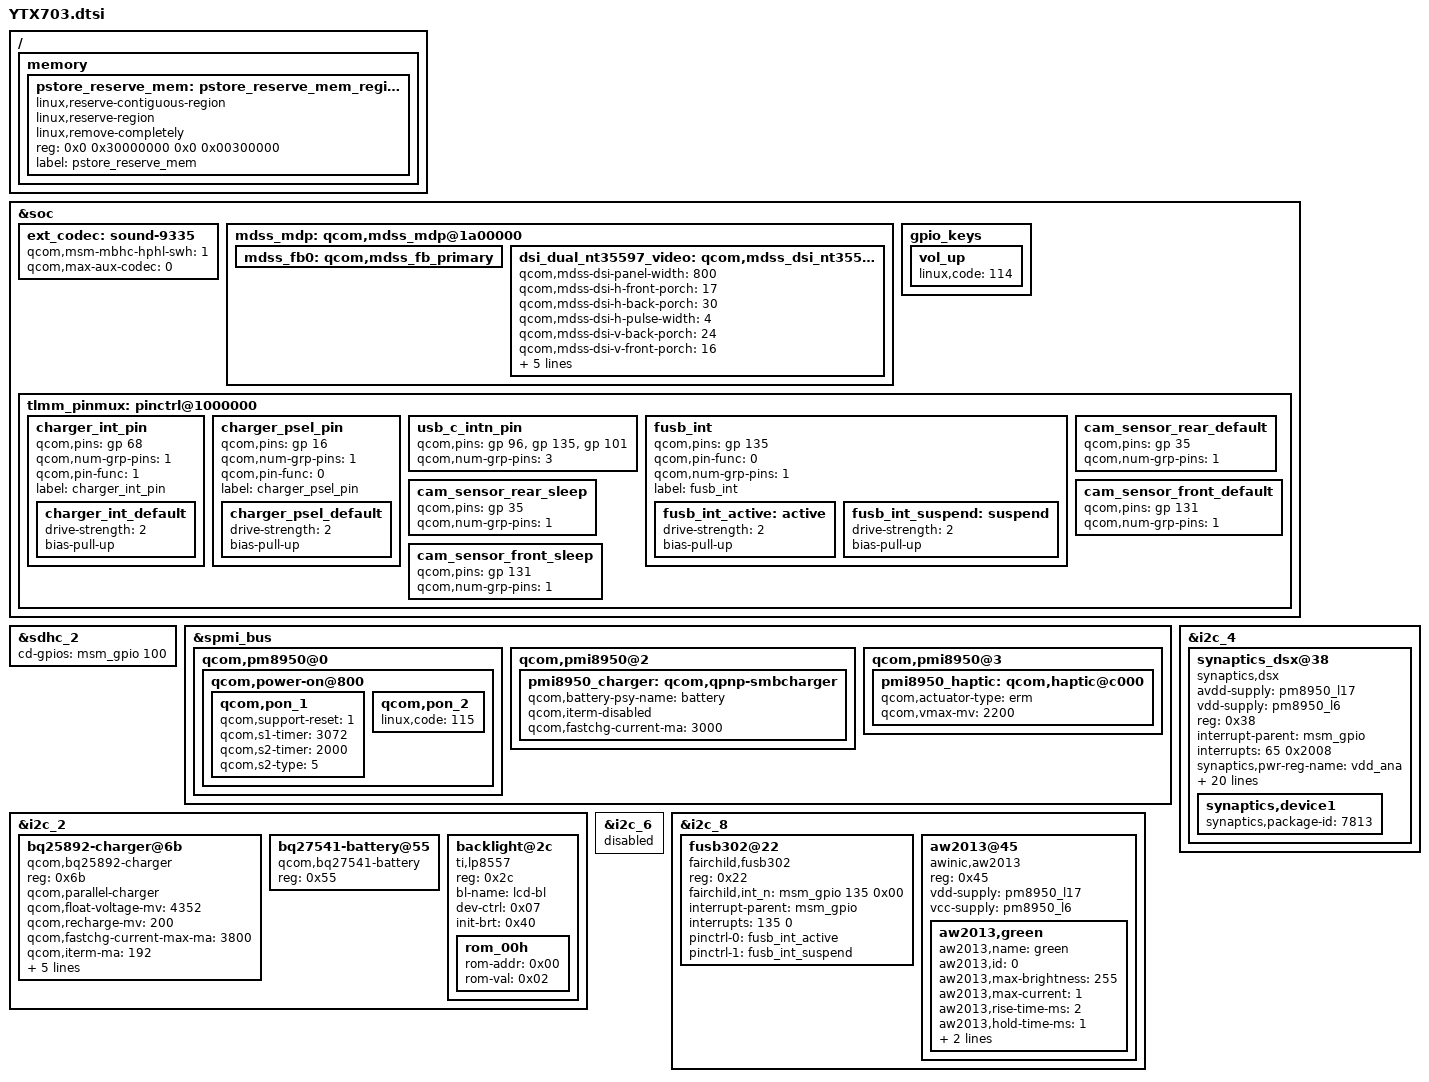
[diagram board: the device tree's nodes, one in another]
/*
 * Copyright (c) 2018, The Linux Foundation. All rights reserved.
 *
 * This program is free software; you can redistribute it and/or modify
 * it under the terms of the GNU General Public License version 2 and
 * only version 2 as published by the Free Software Foundation.
 *
 * This program is distributed in the hope that it will be useful,
 * but WITHOUT ANY WARRANTY; without even the implied warranty of
 * MERCHANTABILITY or FITNESS FOR A PARTICULAR PURPOSE.  See the
 * GNU General Public License for more details.
 */

#include "YTX703-camera-sensor.dtsi"

/ {
	/* reserve memory region for pstore: */
	memory {
		pstore_reserve_mem: pstore_reserve_mem_region@0 {
			linux,reserve-contiguous-region;
			linux,reserve-region;
			linux,remove-completely;
			reg = <0x0 0x30000000 0x0 0x00300000>;
			label = "pstore_reserve_mem";
		};
	};
};

&soc {
	/* sound configuration */
	ext_codec: sound-9335 {
		qcom,msm-mbhc-hphl-swh = <1>; /* headphone detection */
		qcom,max-aux-codec = <0>;
	};
	/* disable kernel boot-logo: */
	mdss_mdp: qcom,mdss_mdp@1a00000 {
		mdss_fb0: qcom,mdss_fb_primary {
			/delete-property/ qcom,mdss-fb-splash-logo-enabled;
		};
	};
	/* Compensate for hardware-reversed VOL-UP and VOL-DOWN buttons */
	gpio_keys {
		vol_up {
			linux,code = <114>; /* KEY_VOLUMEDOWN */
		};
	};
	/* pin configuration */
	tlmm_pinmux: pinctrl@1000000 {
		/* charger pins: */
		charger_int_pin {
			qcom,pins = <&gp 68>;
			qcom,num-grp-pins = <1>;
			qcom,pin-func = <1>;
			label = "charger_int_pin";
			charger_int_default: charger_int_default {
				drive-strength = <2>; /* 2 MA */
				bias-pull-up; /* PULL UP*/
			};
		};
		charger_psel_pin {
			qcom,pins = <&gp 16>;
			qcom,num-grp-pins = <1>;
			qcom,pin-func = <0>;
			label = "charger_psel_pin";
			charger_psel_default:  charger_psel_default {
				drive-strength = <2>; /* 2 MA */
				bias-pull-up; /* PULL UP*/
			};
		};
		/* USB pins: */
		usb_c_intn_pin {
			qcom,pins = <&gp 96>, <&gp 135>, <&gp 101>;
			qcom,num-grp-pins = <3>;
		};
		fusb_int {
			qcom,pins = <&gp 135>;
			qcom,pin-func = <0>;
			qcom,num-grp-pins = <1>;
			label = "fusb_int";
			fusb_int_active: active {
				drive-strength = <2>;
				bias-pull-up;
			};
			fusb_int_suspend: suspend {
				drive-strength = <2>;
				bias-pull-up;
			};
		};
		/* camera pins: */
		cam_sensor_rear_default {  /* STANDBY */
			qcom,pins = <&gp 35>;
			qcom,num-grp-pins = <1>;
		};
		cam_sensor_rear_sleep {    /* STANDBY */
			qcom,pins = <&gp 35>;
			qcom,num-grp-pins = <1>;
		};
		cam_sensor_front_default { /* RESET, STANDBY */
			qcom,pins = <&gp 131>;
			qcom,num-grp-pins = <1>;
		};
		cam_sensor_front_sleep {   /* RESET, STANDBY */
			qcom,pins = <&gp 131>;
			qcom,num-grp-pins = <1>;
		};
	};
};

/* SD-card GPIO */
&sdhc_2 {
	cd-gpios = <&msm_gpio 100 0x0>;
};

/* SPMI configuration */
&spmi_bus {
	/* power-button configuration: */
	qcom,pm8950@0 {
		qcom,power-on@800 {
			qcom,pon_1 {
				qcom,support-reset = <1>;
				qcom,s1-timer = <3072>; /* forced power off */
				qcom,s2-timer = <2000>; /* than reboot */
				qcom,s2-type = <5>;
			};
			/* Compensate for hardware-reversed VOL-UP and VOL-DOWN buttons */
			qcom,pon_2 {
				linux,code = <115>; /* KEY_VOLUMEUP */
			};
		};
	};
	/* smbcharger configuration: */
	qcom,pmi8950@2 {
		pmi8950_charger: qcom,qpnp-smbcharger {
			/delete-property/ qcom,iterm-ma;
			/delete-property/ qcom,float-voltage-mv;
			/delete-property/ qcom,resume-delta-mv;
			qcom,battery-psy-name= "battery";
			/delete-property/ qcom,autoadjust-vfloat;
			/delete-property/ qcom,force-aicl-rerun;
			/delete-property/ qcom,aicl-rerun-period-s;
			/delete-property/ qcom,charging-disabled;
			qcom,iterm-disabled;
			qcom,fastchg-current-ma = <3000>;
		};
	};
	/* vibrator settings: */
	qcom,pmi8950@3 {
		pmi8950_haptic: qcom,haptic@c000 {
			qcom,actuator-type = "erm";
			qcom,vmax-mv = <2200>;
		};
	};
};

/* I2C configuration */
&i2c_2 {
	/* parallel-charger configuration: */
	bq25892-charger@6b {
		compatible = "qcom,bq25892-charger";
		reg = <0x6b>;
		qcom,parallel-charger;
		qcom,float-voltage-mv = <4352>;
		qcom,recharge-mv = <200>;
		qcom,fastchg-current-max-ma = <3800>;
		qcom,iterm-ma = <192>;
		interrupt-parent = <&msm_gpio>;
		interrupts = <68 0>;
		pinctrl-names = "default";
		pinctrl-0 = <&charger_int_default &charger_psel_default>;
		qcom,psel-gpio = <&msm_gpio 16 0>;
	};

	bq27541-battery@55 {
		compatible = "qcom,bq27541-battery";
		reg = <0x55>;
	};

	backlight@2c {
		compatible = "ti,lp8557";
		reg = <0x2c>;
		bl-name = "lcd-bl";
		dev-ctrl = /bits/ 8 <0x07>; /* see lp8557 documentation */
		init-brt = /bits/ 8 <0x40>; /* 25% brightness */
		 /* enable spread-spectrum boost clocking (reduces flickering): */
		rom_00h {
			rom-addr = /bits/ 8 <0x00>;
			rom-val  = /bits/ 8 <0x02>;
		};
	};
};

&i2c_4 { /* BLSP1 QUP4 */
	/delete-node/ synaptics@20;
	/* touchscreen configuration: */
	synaptics_dsx@38 {
		/* use with driver v2.0: */
		compatible  = "synaptics,dsx";
		avdd-supply = <&pm8950_l17>;
		vdd-supply  = <&pm8950_l6>;
		/* use with driver v2.6: */
		//compatible = "synaptics,dsx-i2c";
		//vdd_ana-supply = <&pm8950_l17>;
		//vcc_i2c-supply = <&pm8950_l6>;
		reg = <0x38>;
		interrupt-parent = <&msm_gpio>;
		interrupts       = <65 0x2008>;
		synaptics,pwr-reg-name = "vdd_ana";
		synaptics,bus-reg-name = "vcc_i2c";
		clock-names = "iface_clk", "core_clk";
		clocks = <&clock_gcc clk_gcc_blsp1_ahb_clk>,
		         <&clock_gcc clk_gcc_blsp1_qup4_i2c_apps_clk>;
		/* pins used by touchscreen: */
		pinctrl-names = "pmx_ts_active","pmx_ts_suspend","pmx_ts_release";
		pinctrl-0 = <&ts_int_active  &ts_reset_active>;
		pinctrl-1 = <&ts_int_suspend &ts_reset_suspend>;
		pinctrl-2 = <&ts_release>;
		synaptics,irq-gpio   = <&msm_gpio 65 0x2008>;
		synaptics,reset-gpio = <&msm_gpio 64 0x0>;
		synaptics,disable-gpios;
		synaptics,detect-device;
		synaptics,i2c-pull-up;
		synaptics,ub-i2c-addr = <0x38>;
		synaptics,power-down;
		synaptics,power-delay-ms  = <60>;
		synaptics,reset-on-state  = <0>;
		synaptics,reset-active-ms = <10>;
		synaptics,reset-delay-ms  = <60>;
		synaptics,irq-flags = <0x2008>; /* IRQF_ONESHOT | IRQF_TRIGGER_LOW */
		/* swap and flip to allow rotation hack: */
		synaptics,swap-axes;
		synaptics,y-flip;
		synaptics,device1 {
			synaptics,package-id = <7813>;
		};
	};
};

&i2c_6 { /* BLSP2 QUP2 */
	status = "disabled"; /* disable unused I2C bus */
	/delete-node/ nq@2b; /* remove NFC node */
};

&i2c_8 { /* BLSP2 QUP4 */
	/* USB-controller configuration: */
	fusb302@22 {
		compatible = "fairchild,fusb302";
		reg = <0x22>;
		fairchild,int_n  = <&msm_gpio 135 0x00>;
		interrupt-parent = <&msm_gpio>;
		interrupts = <135 0>; /* MSM GPIO 102 */
		interrupt-names = "fsc_interrupt_int_n";
		pinctrl-names = "fusb_active", "fusb_suspend";
		pinctrl-0 = <&fusb_int_active>;
		pinctrl-1 = <&fusb_int_suspend>;
	};
	/* notification LED configuration: */
	aw2013@45 {
		compatible = "awinic,aw2013";
		reg = <0x45>;
		vdd-supply = <&pm8950_l17>;
		vcc-supply = <&pm8950_l6>;
		aw2013,green {
			aw2013,name = "green";
			aw2013,id = <0>;
			aw2013,max-brightness = <255>;
			aw2013,max-current = <1>;
			aw2013,rise-time-ms = <2>;
			aw2013,hold-time-ms = <1>;
			aw2013,fall-time-ms = <2>;
			aw2013,off-time-ms  = <1>;
		};
	};
};

/* LCD configuration: */
&mdss_mdp {
	dsi_dual_nt35597_video: qcom,mdss_dsi_nt35597_wqxga_video {
		qcom,mdss-dsi-panel-width   = <800>;
		qcom,mdss-dsi-h-front-porch = <17>;  //MIPICLL 399
		qcom,mdss-dsi-h-back-porch  = <30>;  //MIPICLL 399
		qcom,mdss-dsi-h-pulse-width = <4>;
		qcom,mdss-dsi-v-back-porch  = <24>;
		qcom,mdss-dsi-v-front-porch = <16>;
		qcom,mdss-dsi-v-pulse-width = <8>;
		qcom,mdss-dsi-on-command = [
			39 01 00 00 01 00 06 f0 55 aa 52 08 00
			15 01 00 00 01 00 02 c0 0d
			39 01 00 00 01 00 05 b8 03 06 00 00
			39 01 00 00 01 00 05 ff aa 55 a5 80
			15 01 00 00 01 00 02 6f 0f
			15 01 00 00 01 00 02 f7 01
			39 01 00 00 01 00 05 ff aa 55 a5 00
			15 01 00 00 01 00 02 62 01
			15 01 00 00 01 00 02 55 00 //CABC mode (0:off, 1:UI, 2:picture, 3:video), p.229
			15 01 00 00 01 00 02 53 24
			15 01 00 00 01 00 02 51 80
			05 01 00 00 78 00 02 11 00
			05 01 00 00 15 00 02 29 00];
		qcom,mdss-dsi-panel-timings = [D5 32 22 00 60 64 26 34 29 03 04 00]; //MIPICLL 399
	};
};
